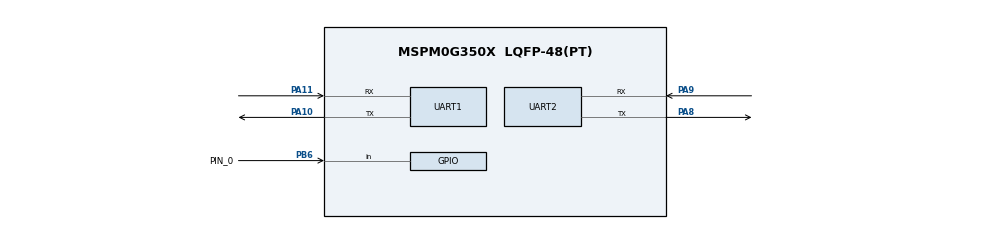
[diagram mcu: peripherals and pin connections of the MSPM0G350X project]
/**
 * @cliArgs --device "MSPM0G350X" --part "Default" --package "LQFP-48(PT)" --product "mspm0_sdk@2.10.00.04"
 * @versions {"tool":"1.26.2+4477"}
 */

/**
 * Import the modules used in this configuration.
 */
const GPIO   = scripting.addModule("/ti/driverlib/GPIO", {}, false);
const GPIO1  = GPIO.addInstance();
const SYSCTL = scripting.addModule("/ti/driverlib/SYSCTL");
const UART   = scripting.addModule("/ti/driverlib/UART", {}, false);
const UART1  = UART.addInstance();
const UART2  = UART.addInstance();

/**
 * Write custom configuration values to the imported modules.
 */
const divider9       = system.clockTree["UDIV"];
divider9.divideValue = 2;

const gate7  = system.clockTree["MFCLKGATE"];
gate7.enable = true;

const multiplier2         = system.clockTree["PLL_QDIV"];
multiplier2.multiplyValue = 5;

const mux8       = system.clockTree["HSCLKMUX"];
mux8.inputSelect = "HSCLKMUX_SYSPLL0";

GPIO1.port                               = "PORTB";
GPIO1.$name                              = "BUTTON_PB6";
GPIO1.associatedPins[0].$name            = "PIN_0";
GPIO1.associatedPins[0].direction        = "INPUT";
GPIO1.associatedPins[0].internalResistor = "PULL_UP";
GPIO1.associatedPins[0].pin.$assign      = "PB6";

const Board = scripting.addModule("/ti/driverlib/Board", {}, false);

SYSCTL.forceDefaultClkConfig = true;
SYSCTL.clockTreeEn           = true;

UART1.$name                    = "UART_0";
UART1.uartClkSrc               = "MFCLK";
UART1.enabledInterrupts        = ["RX"];
UART1.targetBaudRate           = 115200;
UART1.peripheral.$assign       = "UART0";
UART1.peripheral.rxPin.$assign = "PA11";
UART1.peripheral.txPin.$assign = "PA10";
UART1.txPinConfig.$name        = "ti_driverlib_gpio_GPIOPinGeneric0";
UART1.rxPinConfig.$name        = "ti_driverlib_gpio_GPIOPinGeneric1";

UART2.$name                    = "UART_1";
UART2.uartClkSrc               = "MFCLK";
UART2.enabledInterrupts        = ["RX"];
UART2.targetBaudRate           = 115200;
UART2.peripheral.$assign       = "UART1";
UART2.peripheral.rxPin.$assign = "PA9";
UART2.peripheral.txPin.$assign = "PA8";
UART2.txPinConfig.$name        = "ti_driverlib_gpio_GPIOPinGeneric2";
UART2.rxPinConfig.$name        = "ti_driverlib_gpio_GPIOPinGeneric3";

/**
 * Pinmux solution for unlocked pins/peripherals. This ensures that minor changes to the automatic solver in a future
 * version of the tool will not impact the pinmux you originally saw.  These lines can be completely deleted in order to
 * re-solve from scratch.
 */
Board.peripheral.$suggestSolution          = "DEBUGSS";
Board.peripheral.swclkPin.$suggestSolution = "PA20";
Board.peripheral.swdioPin.$suggestSolution = "PA19";
